# G32R501 register map
Vendor: Geehy Semiconductor Co., Ltd.; Series: G32R5; File version: 1.0
CPU: CM55 r0p1, little endian, MPU, FPU, double-precision FPU, DSP, VTOR, 4 interrupt priority bits
Registers are 32-bit, read-write, reset 0x0 unless marked. A register's access mark holds for its fields unless they carry their own. Offsets are from the block's base; [hi:lo] are bit positions; {n}, {i} and the like mark numbered series; 'fields as' and 'values as' point back to an identical list.

## SDF — Sigma delta filter
Base 0x40003C00
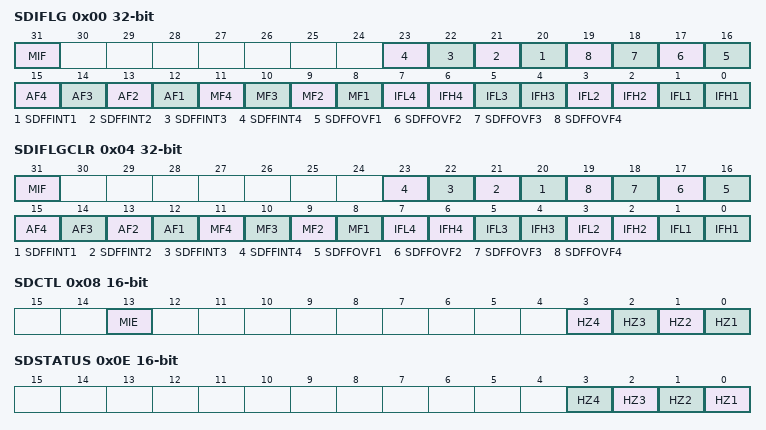
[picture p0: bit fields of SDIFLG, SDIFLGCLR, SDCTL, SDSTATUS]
0x00 SDIFLG — SD Interrupt Flag Register
  [31] MIF — Master Interrupt Flag
  [n+19] SDFFINT{n} (n=1..4) — SDFIFO interrupt for Ch{n}
  [n+15] SDFFOVF{n} (n=1..4) — FIFO Overflow Flag for Ch{n}
  [n+11] AF{n} (n=1..4) — Acknowledge flag for Filter {n}
  [n+7] MF{n} (n=1..4) — Modulator Failure for Filter {n}
  [2n-1] IFL{n} (n=1..4) — Low-level Interrupt flag for Ch{n}
  [2n-2] IFH{n} (n=1..4) — High-level Interrupt flag for Ch{n}
0x04 SDIFLGCLR — SD Interrupt Flag Clear Register
  [31] MIF — Master Interrupt Flag
  [n+19] SDFFINT{n} (n=1..4) — SDFIFO Interrupt flag-clear bit for Ch{n}
  [n+15] SDFFOVF{n} (n=1..4) — SDFIFO overflow clear Ch{n}
  [n+11] AF{n} (n=1..4) — Acknowledge flag for Filter {n}
  [n+7] MF{n} (n=1..4) — Modulator Failure for Filter {n}
  [2n-1] IFL{n} (n=1..4) — Low-level Interrupt flag for Ch{n}
  [2n-2] IFH{n} (n=1..4) — High-level Interrupt flag for Ch{n}
0x08 SDCTL 16-bit — SD Control Register
  [13] MIE — Master SDy_ERR Interrupt enable
  [n-1] HZ{n} (n=1..4) — High-level Threshold crossing (Z) flag Ch{n}
0x0C SDMFILEN 16-bit — SD Master Filter Enable
  [11] MFE — Master Filter Enable
0x0E SDSTATUS 16-bit
  [n-1] HZ{n} (n=1..4) — High-level Threshold crossing (Z) flag Ch{n}
{0x0+0x20*i} SDCTLPARM{i} 16-bit (i=1..4) — Control Parameter Register for Ch{i}
  [1:0] MOD — Modulator clocking modes
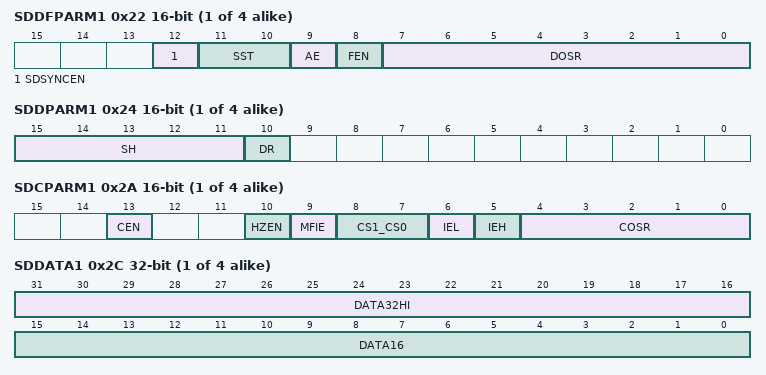
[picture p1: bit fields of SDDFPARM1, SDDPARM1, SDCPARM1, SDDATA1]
{0x2+0x20*i} SDDFPARM{i} 16-bit (i=1..4) — Data Filter Parameter Register for Ch{i}
  [12] SDSYNCEN — Data Filter Reset Enable
  [11:10] SST — Data filter Structure (SincFast/1/2/3)
  [9] AE — Ack Enable
  [8] FEN — Filter Enable
  [7:0] DOSR — Data Filter Oversample Ratio= DOSR+1
{0x4+0x20*i} SDDPARM{i} 16-bit (i=1..4) — Data Parameter Register for Ch{i}
  [15:11] SH — Shift Control (# bits to shift in 16b mode)
  [10] DR — Data Representation (0/1 = 16/32b 2's complement)
{0x6+0x20*i} SDCMPH{i} 16-bit reset 0x7FFF (i=1..4) — High-level Threshold Register for Ch{i}
  [14:0] HLT — High-level threshold for the comparator filter output
{0x8+0x20*i} SDCMPL{i} 16-bit (i=1..4) — Low-level Threshold Register for Ch{i}
  [14:0] LLT — Low-level threshold for the comparator filter output
{0xA+0x20*i} SDCPARM{i} 16-bit (i=1..4) — Comparator Filter Parameter Register for Ch{i}
  [13] CEN — Comparator Enable
  [10] HZEN — High level (Z) Threshold crossing output enable
  [9] MFIE — Modulator Failure Interrupt enable
  [8:7] CS1_CS0 — Comparator Filter Structure (SincFast/1/2/3)
  [6] IEL — Low-level interrupt enable
  [5] IEH — High-level Interrupt enable
  [4:0] COSR — Comparator Oversample Ratio. Actual rate COSR+1
{0xC+0x20*i} SDDATA{i} (i=1..4) — Data Filter Data Register (16 or 32bit) for Ch{i}
  [31:16] DATA32HI — Hi-order 16b in 32b mode, 16-bit Data in 16b mode
  [15:0] DATA16 — Lo-order 16b in 32b mode
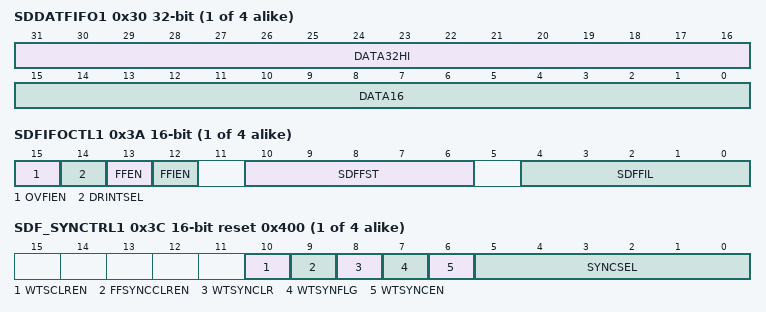
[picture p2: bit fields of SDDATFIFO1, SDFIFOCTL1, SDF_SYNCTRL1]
{0x10+0x20*i} SDDATFIFO{i} (i=1..4) — Filter Data FIFO Output(32b) for Ch{i}
  fields as SDDATA1
{0x14+0x20*i} SDCDATA{i} 16-bit (i=1..4) — Comparator Filter Data Register (16b) for Ch{i}
  [15:0] SDCDATA{i} — Comparator Data output
{0x18+0x20*i} SDCMPHZ{i} 16-bit (i=1..4) — High-level (Z) Threshold Register for Ch{i}
  [14:0] HLTZ — High-level threshold (Z) for the comparator filter output
{0x1A+0x20*i} SDFIFOCTL{i} 16-bit (i=1..4) — FIFO Control Register for Ch{i}
  [15] OVFIEN — SDFIFO Overflow interrupt enable
  [14] DRINTSEL — Data-Ready Interrupt Source Select
  [13] FFEN — SDFIFO Enable
  [12] FFIEN — SDFIFO data ready Interrupt Enable
  [10:6] SDFFST — SDFIFO Status
  [4:0] SDFFIL — SDFIFO Interrupt Level
{0x1C+0x20*i} SDF_SYNCTRL{i} 16-bit reset 0x400 (i=1..4) — SD Filter Sync control for Ch{i}
  [10] WTSCLREN — WTSYNFLG Clear-on-FIFOINT Enable
  [9] FFSYNCCLREN — FIFO Clear-on-SDSYNC Enable
  [8] WTSYNCLR — Wait-for-Sync Flag Clear
  [7] WTSYNFLG — Wait-for-Sync Flag
  [6] WTSYNCEN — Wait-for-Sync Enable
  [5:0] SYNCSEL — SDSYNC Source Select
